# STM32C532 register map
File version: 2.1.0
CPU: CM33 r0p4, little endian, MPU, FPU, 4 interrupt priority bits
Registers are 32-bit, read-write, reset 0x0 unless marked. A register's access mark holds for its fields unless they carry their own. Offsets are from the block's base; [hi:lo] are bit positions.

## SBS — SBS register block
Base 0x44000400
0x10 SBS_HDPLCR reset 0xB4 — SBS temporal isolation control register
  [7:0] INCR_HDPL — HDPL value increment
    180=No increment; 106=Recommended value to increment HDPL level by one
0x14 SBS_HDPLSR ro reset 0x51 — SBS temporal isolation status register
  [7:0] HDPL — Temporal isolation level
    81=HDPL1, hide protection level to be used to execute and protect an immutable root of trust (IROT) stage. First code to be executed at each reset of the platform. To ensure secure boot, this code must be immutable); 138=HDPL2, hide protection level to be used to execute and protect an updatable Root of Trust (UROT) stage. UROT is executed from IROT to complete the immutable root of trust execution during boot stages; 111=HDPL3, hide protection level to be used to execute the application. It is a temporal isolation level that can be used to run the application when it has to be isolated from IROT and UROT)
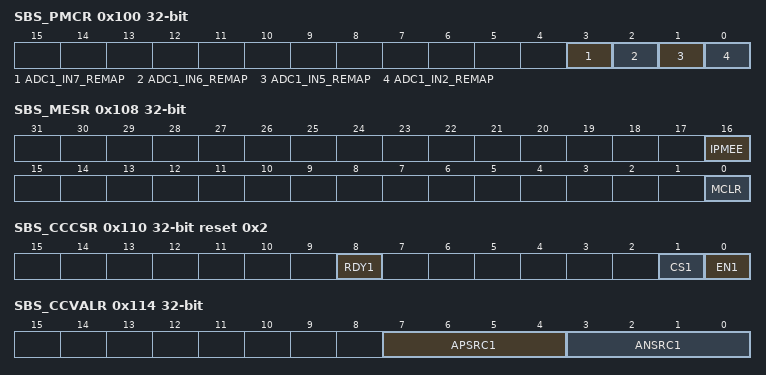
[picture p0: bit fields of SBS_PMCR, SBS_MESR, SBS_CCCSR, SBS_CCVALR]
0x100 SBS_PMCR — SBS product mode and configuration register
  [3] ADC1_IN7_REMAP — ADC1 channel IN7 remap
    0=ADC1_IN7 is mapped on PA7; 1=ADC1_IN7 is mapped on PB1
  [2] ADC1_IN6_REMAP — ADC1 channel IN6 remap
    0=ADC1_IN6 is mapped on PA6; 1=ADC1_IN6 is mapped on PB0
  [1] ADC1_IN5_REMAP — ADC1 channel IN5 remap
    0=ADC1_IN5 is mapped on PA5; 1=ADC1_IN5 is mapped on PC5
  [0] ADC1_IN2_REMAP — ADC1 channel IN2 remap
    0=ADC1_IN2 is mapped on PA2; 1=ADC1_IN2 is mapped on PC4
0x104 SBS_FPUIMR reset 0x1F — SBS FPU interrupt mask register
  [5:0] FPU_IE — FPU interrupt enable
0x108 SBS_MESR (reset mask 0xFFF0FFF0) — SBS memory erase status register
  [16] IPMEE — ICACHE erase status
    0=ICACHE erase ongoing; 1=ICACHE erase ended
  [0] MCLR — Device memories erase status
    0=Memory erase ongoing if not yet cleared by software; 1=Memory erase done
0x110 SBS_CCCSR reset 0x2 — SBS compensation cell for I/Os control and status register
  [8] RDY1 ro — VDDIO compensation cell ready flag
    0=VDDIO compensation cell not ready; 1=VDDIO compensation cell ready (code value provided by the cell can be used)
  [1] CS1 — Code selection for VDDIO power rail (reset value set to 1)
    0=Code from the cell (available in the SBS_CCVALR); 1=Code from SBS_CCWCR
  [0] EN1 — Enable compensation cell for VDDIO power rail
    0=I/O compensation cell disabled; 1=I/O compensation cell enabled
0x114 SBS_CCVALR ro (reset mask 0xFFFFFF00) — SBS compensation cell for I/Os value register
  [7:4] APSRC1 — Compensation value for the PMOS transistor
  [3:0] ANSRC1 — Compensation value for the NMOS transistor
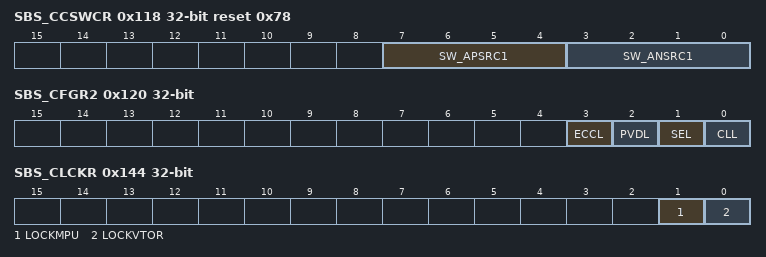
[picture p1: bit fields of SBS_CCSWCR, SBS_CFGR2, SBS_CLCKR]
0x118 SBS_CCSWCR reset 0x78 — SBS compensation cell for I/Os software code register
  [7:4] SW_APSRC1 — PMOS compensation code for the VDD power rails
  [3:0] SW_ANSRC1 — NMOS compensation code for VDD power rails
0x120 SBS_CFGR2 — SBS Class B register
  [3] ECCL — ECC lock
    0=Double ECC error flag disconnected to timer break inputs; 1=Double ECC error flag connected to timer break inputs
  [2] PVDL — PVD lock
    0=PVD interrupt disconnected from timer break inputs. PVD_EN and PVD_SEL[2:0] inPWR registers are read/write.; 1=PVD interrupt is connected to timer break inputs. PVD_EN and PVD_SEL[2:0] in PWR registers are read only
  [1] SEL — SRAM ECC error lock
    0=SRAM double ECC error flag disconnected from timer break inputs; 1=SRAM double ECC error flag connected to timer break inputs
  [0] CLL — Core lockup lock
    0=Lockup output disconnected from timer break inputs; 1=Lockup output connected to timer break inputs
0x144 SBS_CLCKR — SBS CPU lock register
  [1] LOCKMPU — MPU register lock
    0=MPU registers write enabled; 1=MPU registers write disabled
  [0] LOCKVTOR — VTOR register lock
    0=VTOR register write enabled; 1=VTOR register write disabled
0x14C SBS_ECCNMIR — SBS ECC NMI mask register
  [0] ECCNMI_MASK_EN — NMI behavior setup when a double ECC error occurs on FLASH data part
    0=NMI generated if a double ECC error in the FLASH data part; 1=NMI not generated if a double ECC error in the FLASH data part
